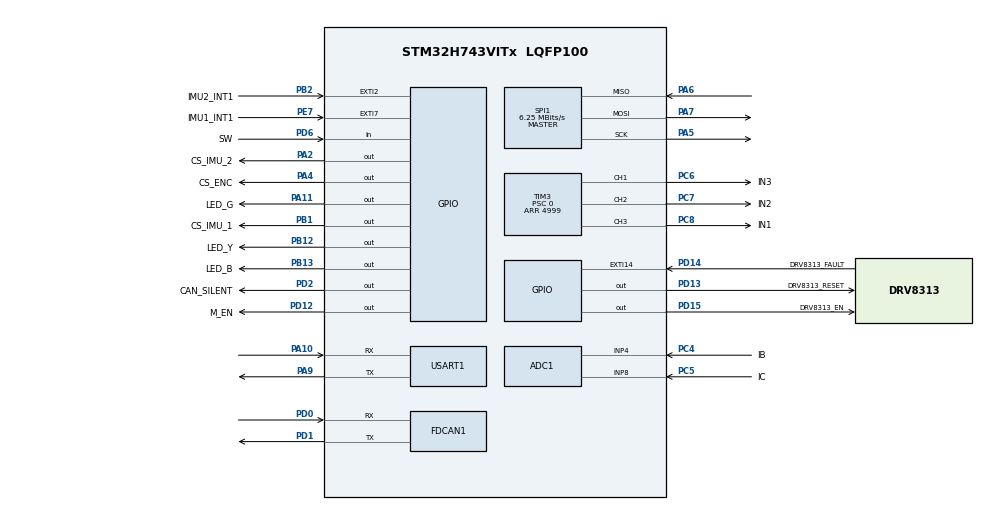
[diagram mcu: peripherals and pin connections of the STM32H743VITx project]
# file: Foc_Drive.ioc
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ADC1.Channel-1\#ChannelRegularConversion=ADC_CHANNEL_4
ADC1.Channel-2\#ChannelRegularConversion=ADC_CHANNEL_8
ADC1.ConversionDataManagement=ADC_CONVERSIONDATA_DMA_CIRCULAR
ADC1.EOCSelection=ADC_EOC_SEQ_CONV
ADC1.ExternalTrigConv=ADC_EXTERNALTRIG_T3_TRGO
ADC1.ExternalTrigConvEdge=ADC_EXTERNALTRIGCONVEDGE_RISING
ADC1.NbrOfConversion=2
ADC1.NbrOfConversionFlag=1
ADC1.OffsetNumber-1\#ChannelRegularConversion=ADC_OFFSET_NONE
ADC1.OffsetNumber-2\#ChannelRegularConversion=ADC_OFFSET_NONE
ADC1.OffsetSignedSaturation-1\#ChannelRegularConversion=DISABLE
ADC1.OffsetSignedSaturation-2\#ChannelRegularConversion=DISABLE
ADC1.Overrun=ADC_OVR_DATA_OVERWRITTEN
ADC1.Rank-1\#ChannelRegularConversion=1
ADC1.Rank-2\#ChannelRegularConversion=2
ADC1.SamplingTime-1\#ChannelRegularConversion=ADC_SAMPLETIME_16CYCLES_5
ADC1.SamplingTime-2\#ChannelRegularConversion=ADC_SAMPLETIME_16CYCLES_5
ADC1.master=1
CORTEX_M7.CPU_DCache=Disabled
CORTEX_M7.CPU_ICache=Enabled
CORTEX_M7.default_mode_Activation=1
Dma.ADC1.0.Direction=DMA_PERIPH_TO_MEMORY
Dma.ADC1.0.EventEnable=DISABLE
Dma.ADC1.0.FIFOMode=DMA_FIFOMODE_DISABLE
Dma.ADC1.0.Instance=DMA1_Stream0
Dma.ADC1.0.MemDataAlignment=DMA_MDATAALIGN_HALFWORD
Dma.ADC1.0.MemInc=DMA_MINC_ENABLE
Dma.ADC1.0.Mode=DMA_CIRCULAR
Dma.ADC1.0.PeriphDataAlignment=DMA_PDATAALIGN_HALFWORD
Dma.ADC1.0.PeriphInc=DMA_PINC_DISABLE
Dma.ADC1.0.Polarity=HAL_DMAMUX_REQ_GEN_RISING
Dma.ADC1.0.Priority=DMA_PRIORITY_HIGH
Dma.ADC1.0.RequestNumber=1
Dma.ADC1.0.SignalID=NONE
Dma.ADC1.0.SyncEnable=DISABLE
Dma.ADC1.0.SyncPolarity=HAL_DMAMUX_SYNC_NO_EVENT
Dma.ADC1.0.SyncRequestNumber=1
Dma.ADC1.0.SyncSignalID=NONE
Dma.Request0=ADC1
FDCAN1.AutoRetransmission=ENABLE
FDCAN1.CalculateBaudRateNominal=1000000
FDCAN1.CalculateTimeBitNominal=1000
FDCAN1.CalculateTimeQuantumNominal=40.0
FDCAN1.NominalPrescaler=1
FDCAN1.NominalSyncJumpWidth=5
FDCAN1.NominalTimeSeg1=19
FDCAN1.NominalTimeSeg2=5
FDCAN1.RxFifo0ElmtsNbr=8
FDCAN1.StdFiltersNbr=1
FDCAN1.TxFifoQueueElmtsNbr=8
Mcu.Family=STM32H7
Mcu.Name=STM32H743VITx
Mcu.Package=LQFP100
NVIC.DMA1_Stream0_IRQn=true\:1\:0\:false\:false\:true\:false\:true\:true
NVIC.EXTI15_10_IRQn=true\:0\:0\:false\:false\:true\:true\:true\:true
NVIC.EXTI2_IRQn=true\:6\:0\:false\:false\:true\:true\:true\:true
NVIC.EXTI9_5_IRQn=true\:6\:0\:false\:false\:true\:true\:true\:true
NVIC.FDCAN1_IT0_IRQn=true\:5\:0\:false\:false\:true\:true\:true\:true
NVIC.PriorityGroup=NVIC_PRIORITYGROUP_4
PA10.Mode=Asynchronous
PA10.Signal=USART1_RX
PA11.GPIO_Label=LED_G
PA11.GPIO_ModeDefaultOutputPP=GPIO_MODE_OUTPUT_PP
PA11.GPIO_Speed=GPIO_SPEED_FREQ_HIGH
PA11.PinState=GPIO_PIN_RESET
PA11.Signal=GPIO_Output
PA13\ (JTMS/SWDIO).Mode=Serial_Wire
PA13\ (JTMS/SWDIO).Signal=DEBUG_JTMS-SWDIO
PA14\ (JTCK/SWCLK).Mode=Serial_Wire
PA14\ (JTCK/SWCLK).Signal=DEBUG_JTCK-SWCLK
PA2.GPIO_Label=CS_IMU_2
PA2.GPIO_ModeDefaultOutputPP=GPIO_MODE_OUTPUT_PP
PA2.GPIO_PuPd=GPIO_NOPULL
PA2.GPIO_Speed=GPIO_SPEED_FREQ_HIGH
PA2.PinState=GPIO_PIN_SET
PA2.Signal=GPIO_Output
PA4.GPIO_Label=CS_ENC
PA4.GPIO_ModeDefaultOutputPP=GPIO_MODE_OUTPUT_PP
PA4.GPIO_PuPd=GPIO_NOPULL
PA4.GPIO_Speed=GPIO_SPEED_FREQ_HIGH
PA4.PinState=GPIO_PIN_SET
PA4.Signal=GPIO_Output
PA5.Mode=Full_Duplex_Master
PA5.Signal=SPI1_SCK
PA6.Mode=Full_Duplex_Master
PA6.Signal=SPI1_MISO
PA7.Mode=Full_Duplex_Master
PA7.Signal=SPI1_MOSI
PA9.Mode=Asynchronous
PA9.Signal=USART1_TX
PB1.GPIO_Label=CS_IMU_1
PB1.GPIO_Speed=GPIO_SPEED_FREQ_HIGH
PB1.PinState=GPIO_PIN_SET
PB1.Signal=GPIO_Output
PB12.GPIO_Label=LED_Y
PB12.GPIO_Speed=GPIO_SPEED_FREQ_HIGH
PB12.PinState=GPIO_PIN_RESET
PB12.Signal=GPIO_Output
PB13.GPIO_Label=LED_B
PB13.GPIO_Speed=GPIO_SPEED_FREQ_HIGH
PB13.Signal=GPIO_Output
PB2.GPIO_Label=IMU2_INT1
PB2.Signal=GPXTI2
PC4.GPIO_Label=IB
PC4.Signal=ADCx_INP4
PC5.GPIO_Label=IC
PC5.Signal=ADCx_INP8
PC6.GPIO_Label=IN3
PC6.GPIO_Speed=GPIO_SPEED_FREQ_HIGH
PC6.Signal=S_TIM3_CH1
PC7.GPIO_Label=IN2
PC7.GPIO_Speed=GPIO_SPEED_FREQ_HIGH
PC7.Signal=S_TIM3_CH2
PC8.GPIO_Label=IN1
PC8.GPIO_Speed=GPIO_SPEED_FREQ_HIGH
PC8.Signal=S_TIM3_CH3
PD0.Mode=FDCAN_Activate
PD0.Signal=FDCAN1_RX
PD1.Mode=FDCAN_Activate
PD1.Signal=FDCAN1_TX
PD12.GPIO_Label=M_EN
PD12.GPIO_Speed=GPIO_SPEED_FREQ_HIGH
PD12.Signal=GPIO_Output
PD13.GPIO_Label=DRV8313_RESET
PD13.GPIO_Speed=GPIO_SPEED_FREQ_HIGH
PD13.Signal=GPIO_Output
PD14.GPIO_Label=DRV8313_FAULT
PD14.GPIO_ModeDefaultEXTI=GPIO_MODE_IT_FALLING
PD14.GPIO_PuPd=GPIO_PULLUP
PD14.Signal=GPXTI14
PD15.GPIO_Label=DRV8313_EN
PD15.GPIO_Speed=GPIO_SPEED_FREQ_HIGH
PD15.Signal=GPIO_Output
PD2.GPIO_Label=CAN_SILENT
PD2.GPIO_Speed=GPIO_SPEED_FREQ_HIGH
PD2.Signal=GPIO_Output
PD6.GPIO_Label=SW
PD6.GPIO_PuPd=GPIO_PULLUP
PD6.Signal=GPIO_Input
PE7.GPIO_Label=IMU1_INT1
PE7.Signal=GPXTI7
PH0-OSC_IN\ (PH0).Mode=HSE-External-Oscillator
PH0-OSC_IN\ (PH0).Signal=RCC_OSC_IN
PH1-OSC_OUT\ (PH1).Mode=HSE-External-Oscillator
PH1-OSC_OUT\ (PH1).Signal=RCC_OSC_OUT
ProjectManager.HeapSize=0x400
ProjectManager.StackSize=0x1000
ProjectManager.TargetToolchain=CMake
RCC.ADCCLockSelection=RCC_ADCCLKSOURCE_PLL2
RCC.ADCFreq_Value=40000000
RCC.APB1Freq_Value=100000000
RCC.APB2Freq_Value=100000000
RCC.APB3Freq_Value=100000000
RCC.APB4Freq_Value=100000000
RCC.CKPERSourceSelection=RCC_CLKPSOURCE_HSE
RCC.CortexFreq_Value=400000000
RCC.D1PPRE=RCC_APB3_DIV2
RCC.D2PPRE1=RCC_APB1_DIV2
RCC.D2PPRE2=RCC_APB2_DIV2
RCC.D3PPRE=RCC_APB4_DIV2
RCC.DIVM1=2
RCC.DIVM2=5
RCC.DIVN1=64
RCC.DIVN2=80
RCC.DIVP2=10
RCC.DIVQ1=4
RCC.DIVQ2=10
RCC.DIVR1=4
RCC.DIVR2=10
RCC.FDCANCLockSelection=RCC_FDCANCLKSOURCE_HSE
RCC.HCLKFreq_Value=200000000
RCC.HPRE=RCC_HCLK_DIV2
RCC.PLL2FRACN=0
RCC.PLLSourceVirtual=RCC_PLLSOURCE_HSE
RCC.SYSCLKFreq_VALUE=400000000
RCC.SYSCLKSource=RCC_SYSCLKSOURCE_PLLCLK
RCC.USBFreq_Value=200000000
SH.ADCx_INP4.0=ADC1_INP4,IN4-Single-Ended
SH.ADCx_INP8.0=ADC1_INP8,IN8-Single-Ended
SH.S_TIM3_CH1.0=TIM3_CH1,PWM Generation1 CH1
SH.S_TIM3_CH2.0=TIM3_CH2,PWM Generation2 CH2
SH.S_TIM3_CH3.0=TIM3_CH3,PWM Generation3 CH3
SPI1.BaudRatePrescaler=SPI_BAUDRATEPRESCALER_32
SPI1.CalculateBaudRate=6.25 MBits/s
SPI1.DataSize=SPI_DATASIZE_8BIT
SPI1.Direction=SPI_DIRECTION_2LINES
SPI1.Mode=SPI_MODE_MASTER
SPI1.VirtualType=VM_MASTER
TIM3.AutoReloadPreload=TIM_AUTORELOAD_PRELOAD_ENABLE
TIM3.Channel-PWM\ Generation1\ CH1=TIM_CHANNEL_1
TIM3.Channel-PWM\ Generation2\ CH2=TIM_CHANNEL_2
TIM3.Channel-PWM\ Generation3\ CH3=TIM_CHANNEL_3
TIM3.Channel-PWM\ Generation4\ No\ Output=TIM_CHANNEL_4
TIM3.CounterMode=TIM_COUNTERMODE_CENTERALIGNED1
TIM3.Period=4999
TIM3.Prescaler=0
TIM3.Pulse-PWM\ Generation1\ CH1=0
TIM3.Pulse-PWM\ Generation2\ CH2=0
TIM3.Pulse-PWM\ Generation3\ CH3=0
TIM3.Pulse-PWM\ Generation4\ No\ Output=4990
TIM3.TIM_MasterOutputTrigger=TIM_TRGO_OC4REF
USART1.VirtualMode-Asynchronous=VM_ASYNC
VP_MEMORYMAP_VS_MEMORYMAP.Mode=CurAppReg
VP_TIM3_VS_ClockSourceINT.Mode=Internal
VP_TIM3_VS_no_output4.Mode=PWM Generation4 No Output
board=custom

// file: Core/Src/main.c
/* USER CODE BEGIN Header */
/**
  ******************************************************************************
  * @file           : main.c
  * @brief          : Main program body
  ******************************************************************************
  * @attention
  *
  * Copyright (c) 2026 STMicroelectronics.
  * All rights reserved.
  *
  * This software is licensed under terms that can be found in the LICENSE file
  * in the root directory of this software component.
  * If no LICENSE file comes with this software, it is provided AS-IS.
  *
  ******************************************************************************
  */
/* USER CODE END Header */
#include "main.h"
#include "adc.h"
#include "dma.h"
#include "fdcan.h"
#include "spi.h"
#include "stm32h7xx_hal_gpio.h"
#include "tim.h"
#include "usart.h"
#include "gpio.h"

/* USER CODE BEGIN Includes */
#include "motor_driver.h"
/* USER CODE END Includes */

void SystemClock_Config(void);
static void MPU_Config(void);

int main(void)
{

  /* MPU Configuration--------------------------------------------------------*/
  MPU_Config();

  /* Enable the CPU Cache */

  /* Enable I-Cache---------------------------------------------------------*/
  SCB_EnableICache();

  /* MCU Configuration--------------------------------------------------------*/

  /* Reset of all peripherals, Initializes the Flash interface and the Systick. */
  HAL_Init();

  /* Configure the system clock */
  SystemClock_Config();

  /* Initialize all configured peripherals */
  MX_GPIO_Init();
  MX_DMA_Init();
  MX_ADC1_Init();
  MX_FDCAN1_Init();
  MX_SPI1_Init();
  MX_USART1_UART_Init();
  MX_TIM3_Init();
  /* USER CODE BEGIN 2 */
  if (MotorDriver_Init() != MOTOR_DRIVER_STATUS_OK)
  {
    Error_Handler();
  }
  /* USER CODE END 2 */

  /* Infinite loop */
  /* USER CODE BEGIN WHILE */
  HAL_GPIO_WritePin(LED_G_GPIO_Port,LED_G_Pin, GPIO_PIN_SET);
  HAL_GPIO_WritePin(LED_Y_GPIO_Port,LED_Y_Pin, GPIO_PIN_SET);

  while (1)
  {
    /* USER CODE END WHILE */

    /* USER CODE BEGIN 3 */
    HAL_GPIO_WritePin(LED_B_GPIO_Port,LED_B_Pin, GPIO_PIN_SET);
    HAL_Delay(500);
    HAL_GPIO_WritePin(LED_B_GPIO_Port,LED_B_Pin, GPIO_PIN_RESET);
    HAL_Delay(500);

  }
  /* USER CODE END 3 */
}

void SystemClock_Config(void)
{
  RCC_OscInitTypeDef RCC_OscInitStruct = {0};
  RCC_ClkInitTypeDef RCC_ClkInitStruct = {0};

  /** Supply configuration update enable
  */
  HAL_PWREx_ConfigSupply(PWR_LDO_SUPPLY);

  /** Configure the main internal regulator output voltage
  */
  __HAL_PWR_VOLTAGESCALING_CONFIG(PWR_REGULATOR_VOLTAGE_SCALE1);

  while(!__HAL_PWR_GET_FLAG(PWR_FLAG_VOSRDY)) {}

  /** Initializes the RCC Oscillators according to the specified parameters
  * in the RCC_OscInitTypeDef structure.
  */
  RCC_OscInitStruct.OscillatorType = RCC_OSCILLATORTYPE_HSE;
  RCC_OscInitStruct.HSEState = RCC_HSE_ON;
  RCC_OscInitStruct.PLL.PLLState = RCC_PLL_ON;
  RCC_OscInitStruct.PLL.PLLSource = RCC_PLLSOURCE_HSE;
  RCC_OscInitStruct.PLL.PLLM = 2;
  RCC_OscInitStruct.PLL.PLLN = 64;
  RCC_OscInitStruct.PLL.PLLP = 2;
  RCC_OscInitStruct.PLL.PLLQ = 4;
  RCC_OscInitStruct.PLL.PLLR = 4;
  RCC_OscInitStruct.PLL.PLLRGE = RCC_PLL1VCIRANGE_3;
  RCC_OscInitStruct.PLL.PLLVCOSEL = RCC_PLL1VCOWIDE;
  RCC_OscInitStruct.PLL.PLLFRACN = 0;
  if (HAL_RCC_OscConfig(&RCC_OscInitStruct) != HAL_OK)
  {
    Error_Handler();
  }

  /** Initializes the CPU, AHB and APB buses clocks
  */
  RCC_ClkInitStruct.ClockType = RCC_CLOCKTYPE_HCLK|RCC_CLOCKTYPE_SYSCLK
                              |RCC_CLOCKTYPE_PCLK1|RCC_CLOCKTYPE_PCLK2
                              |RCC_CLOCKTYPE_D3PCLK1|RCC_CLOCKTYPE_D1PCLK1;
  RCC_ClkInitStruct.SYSCLKSource = RCC_SYSCLKSOURCE_PLLCLK;
  RCC_ClkInitStruct.SYSCLKDivider = RCC_SYSCLK_DIV1;
  RCC_ClkInitStruct.AHBCLKDivider = RCC_HCLK_DIV2;
  RCC_ClkInitStruct.APB3CLKDivider = RCC_APB3_DIV2;
  RCC_ClkInitStruct.APB1CLKDivider = RCC_APB1_DIV2;
  RCC_ClkInitStruct.APB2CLKDivider = RCC_APB2_DIV2;
  RCC_ClkInitStruct.APB4CLKDivider = RCC_APB4_DIV2;

  if (HAL_RCC_ClockConfig(&RCC_ClkInitStruct, FLASH_LATENCY_2) != HAL_OK)
  {
    Error_Handler();
  }
}

/* USER CODE BEGIN 4 */

/**
  * @brief Dispatch GPIO interrupts that belong to application-level modules.
  * @param GPIO_Pin GPIO pin mask supplied by the STM32 HAL EXTI dispatcher.
  * @retval None
  */
void HAL_GPIO_EXTI_Callback(uint16_t GPIO_Pin)
{
  if (GPIO_Pin == DRV8313_FAULT_Pin)
  {
    MotorDriver_HandleFaultInterrupt();
  }
}

/* USER CODE END 4 */

 /* MPU Configuration */

void MPU_Config(void)
{
  MPU_Region_InitTypeDef MPU_InitStruct = {0};

  /* Disables the MPU */
  HAL_MPU_Disable();

  /** Initializes and configures the Region and the memory to be protected
  */
  MPU_InitStruct.Enable = MPU_REGION_ENABLE;
  MPU_InitStruct.Number = MPU_REGION_NUMBER0;
  MPU_InitStruct.BaseAddress = 0x0;
  MPU_InitStruct.Size = MPU_REGION_SIZE_4GB;
  MPU_InitStruct.SubRegionDisable = 0x87;
  MPU_InitStruct.TypeExtField = MPU_TEX_LEVEL0;
  MPU_InitStruct.AccessPermission = MPU_REGION_NO_ACCESS;
  MPU_InitStruct.DisableExec = MPU_INSTRUCTION_ACCESS_DISABLE;
  MPU_InitStruct.IsShareable = MPU_ACCESS_SHAREABLE;
  MPU_InitStruct.IsCacheable = MPU_ACCESS_NOT_CACHEABLE;
  MPU_InitStruct.IsBufferable = MPU_ACCESS_NOT_BUFFERABLE;

  HAL_MPU_ConfigRegion(&MPU_InitStruct);
  /* Enables the MPU */
  HAL_MPU_Enable(MPU_PRIVILEGED_DEFAULT);

}

void Error_Handler(void)
{
  __disable_irq();
  while (1)
  {
  }
}
